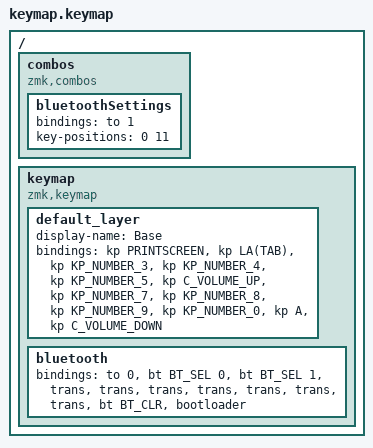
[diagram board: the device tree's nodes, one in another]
#include "zmk-helpers/helper.h"
#include <behaviors.dtsi>
#include <dt-bindings/zmk/bt.h>
#include <dt-bindings/zmk/keys.h>

/ {
    combos {
        compatible = "zmk,combos";

        bluetoothSettings {
            bindings = <&to 1>;
            key-positions = <0 11>;
        };
    };

    keymap {
        compatible = "zmk,keymap";

        default_layer {
            display-name = "Base";
            bindings = <
&kp PRINTSCREEN  &kp LA(TAB)  &kp KP_NUMBER_3  &kp KP_NUMBER_4  &kp KP_NUMBER_5  &kp C_VOLUME_UP  &kp KP_NUMBER_7  &kp KP_NUMBER_8  &kp KP_NUMBER_9  &kp KP_NUMBER_0  &kp A  &kp C_VOLUME_DOWN
            >;
        };

        bluetooth {
            bindings = <
&to 0  &bt BT_SEL 0  &bt BT_SEL 1  &trans  &trans  &trans  &trans  &trans  &trans  &trans  &bt BT_CLR  &bootloader
            >;
        };
    };
};
